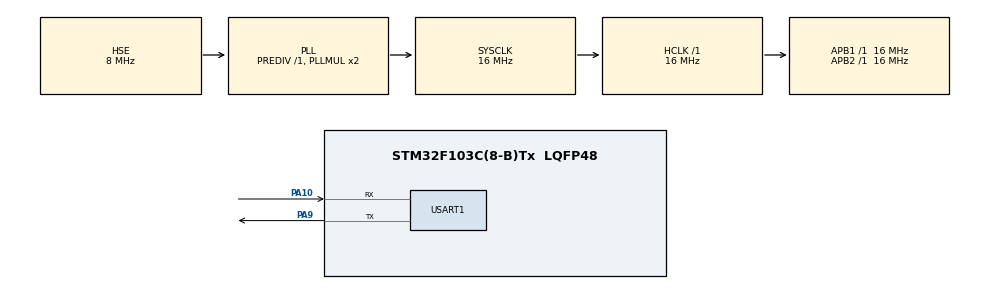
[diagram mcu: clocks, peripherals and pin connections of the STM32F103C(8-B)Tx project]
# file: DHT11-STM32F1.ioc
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Mcu.Family=STM32F1
Mcu.Name=STM32F103C(8-B)Tx
Mcu.Package=LQFP48
NVIC.PriorityGroup=NVIC_PRIORITYGROUP_4
PA10.Mode=Asynchronous
PA10.Signal=USART1_RX
PA9.Mode=Asynchronous
PA9.Signal=USART1_TX
PD0-OSC_IN.Mode=HSE-External-Oscillator
PD0-OSC_IN.Signal=RCC_OSC_IN
PD1-OSC_OUT.Mode=HSE-External-Oscillator
PD1-OSC_OUT.Signal=RCC_OSC_OUT
ProjectManager.TargetToolchain=MDK-ARM 4.73
RCC.AHBFreq_Value=16000000
RCC.APB1Freq_Value=16000000
RCC.APB1TimFreq_Value=16000000
RCC.APB2Freq_Value=16000000
RCC.APB2TimFreq_Value=16000000
RCC.HCLKFreq_Value=16000000
RCC.HSIState=RCC_HSI_ON
RCC.PLLSourceVirtual=RCC_PLLSOURCE_HSE
RCC.SYSCLKFreq_VALUE=16000000
RCC.SYSCLKSource=RCC_SYSCLKSOURCE_PLLCLK
RCC.USBFreq_Value=16000000

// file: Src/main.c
/**
  ******************************************************************************
  * File Name          : main.c
  * Date               : 17/05/2015 16:27:30
  * Description        : Main program body
  ******************************************************************************
  *
  * COPYRIGHT(c) 2015 STMicroelectronics
  *
  * Redistribution and use in source and binary forms, with or without modification,
  * are permitted provided that the following conditions are met:
  *   1. Redistributions of source code must retain the above copyright notice,
  *      this list of conditions and the following disclaimer.
  *   2. Redistributions in binary form must reproduce the above copyright notice,
  *      this list of conditions and the following disclaimer in the documentation
  *      and/or other materials provided with the distribution.
  *   3. Neither the name of STMicroelectronics nor the names of its contributors
  *      may be used to endorse or promote products derived from this software
  *      without specific prior written permission.
  *
  * THIS SOFTWARE IS PROVIDED BY THE COPYRIGHT HOLDERS AND CONTRIBUTORS "AS IS"
  * AND ANY EXPRESS OR IMPLIED WARRANTIES, INCLUDING, BUT NOT LIMITED TO, THE
  * IMPLIED WARRANTIES OF MERCHANTABILITY AND FITNESS FOR A PARTICULAR PURPOSE ARE
  * DISCLAIMED. IN NO EVENT SHALL THE COPYRIGHT HOLDER OR CONTRIBUTORS BE LIABLE
  * FOR ANY DIRECT, INDIRECT, INCIDENTAL, SPECIAL, EXEMPLARY, OR CONSEQUENTIAL
  * DAMAGES (INCLUDING, BUT NOT LIMITED TO, PROCUREMENT OF SUBSTITUTE GOODS OR
  * SERVICES; LOSS OF USE, DATA, OR PROFITS; OR BUSINESS INTERRUPTION) HOWEVER
  * CAUSED AND ON ANY THEORY OF LIABILITY, WHETHER IN CONTRACT, STRICT LIABILITY,
  * OR TORT (INCLUDING NEGLIGENCE OR OTHERWISE) ARISING IN ANY WAY OUT OF THE USE
  * OF THIS SOFTWARE, EVEN IF ADVISED OF THE POSSIBILITY OF SUCH DAMAGE.
  *
  ******************************************************************************
  */

#include "stm32f1xx_hal.h"
#include <stdio.h>

UART_HandleTypeDef huart1;

void SystemClock_Config(void);
static void MX_GPIO_Init(void);
static void MX_USART1_UART_Init(void);

#ifdef __GNUC__
  /* With GCC/RAISONANCE, small printf (option LD Linker->Libraries->Small printf
     set to 'Yes') calls __io_putchar() */
  #define PUTCHAR_PROTOTYPE int __io_putchar(int ch)
#else
  #define PUTCHAR_PROTOTYPE int fputc(int ch, FILE *f)
	//#define PUTCHAR_PROTOTYPE int fputs(const char *s, FILE *f)
#endif /* __GNUC__ */

int main(void)
{

  /* MCU Configuration----------------------------------------------------------*/

  /* Reset of all peripherals, Initializes the Flash interface and the Systick. */
  HAL_Init();

  /* Configure the system clock */
  SystemClock_Config();

  /* Initialize all configured peripherals */
  MX_GPIO_Init();
  MX_USART1_UART_Init();

  /* USER CODE BEGIN 3 */
  /* Infinite loop */
	uint8_t cnt;
	cnt = 0;
  while (1)
  {
		cnt++;
		printf("cnt = %d\n", cnt);
		HAL_Delay(2000);						// Delay 2s
  }
  /* USER CODE END 3 */

}

/** System Clock Configuration
*/
void SystemClock_Config(void)
{

  RCC_OscInitTypeDef RCC_OscInitStruct;
  RCC_ClkInitTypeDef RCC_ClkInitStruct;

  RCC_OscInitStruct.OscillatorType = RCC_OSCILLATORTYPE_HSE;
  RCC_OscInitStruct.HSEState = RCC_HSE_ON;
  RCC_OscInitStruct.HSEPredivValue = RCC_HSE_PREDIV_DIV1;
  RCC_OscInitStruct.PLL.PLLState = RCC_PLL_ON;
  RCC_OscInitStruct.PLL.PLLSource = RCC_PLLSOURCE_HSE;
  RCC_OscInitStruct.PLL.PLLMUL = RCC_PLL_MUL2;
  HAL_RCC_OscConfig(&RCC_OscInitStruct);

  RCC_ClkInitStruct.ClockType = RCC_CLOCKTYPE_SYSCLK;
  RCC_ClkInitStruct.SYSCLKSource = RCC_SYSCLKSOURCE_PLLCLK;
  RCC_ClkInitStruct.AHBCLKDivider = RCC_SYSCLK_DIV1;
  RCC_ClkInitStruct.APB1CLKDivider = RCC_HCLK_DIV1;
  RCC_ClkInitStruct.APB2CLKDivider = RCC_HCLK_DIV1;
  HAL_RCC_ClockConfig(&RCC_ClkInitStruct, FLASH_LATENCY_0);

  __HAL_RCC_AFIO_CLK_ENABLE();

}

/* USART1 init function */
void MX_USART1_UART_Init(void)
{

  huart1.Instance = USART1;
  huart1.Init.BaudRate = 115200;
  huart1.Init.WordLength = UART_WORDLENGTH_8B;
  huart1.Init.StopBits = UART_STOPBITS_1;
  huart1.Init.Parity = UART_PARITY_NONE;
  huart1.Init.Mode = UART_MODE_TX_RX;
  huart1.Init.HwFlowCtl = UART_HWCONTROL_NONE;
  huart1.Init.OverSampling = UART_OVERSAMPLING_16;
  HAL_UART_Init(&huart1);

}

/** Configure pins as
        * Analog
        * Input
        * Output
        * EVENT_OUT
        * EXTI
*/
void MX_GPIO_Init(void)
{

  /* GPIO Ports Clock Enable */
  __GPIOD_CLK_ENABLE();
  __GPIOA_CLK_ENABLE();

}

/* USER CODE BEGIN 4 */

/**
  * @brief  Retargets the C library printf function to the USART.
  * @param  None
  * @retval None
  */
PUTCHAR_PROTOTYPE
{
  /* Place your implementation of fputc here */
  /* e.g. write a character to the USART */
  HAL_UART_Transmit(&huart1, (uint8_t *) &ch, 1, 0xFFFF );

  /* Loop until transmit data register is empty */
  while (HAL_UART_GetState(&huart1) == HAL_UART_STATE_BUSY_TX)
  {}

  return ch;
}

/* USER CODE END 4 */

/************************ (C) COPYRIGHT STMicroelectronics *****END OF FILE****/
